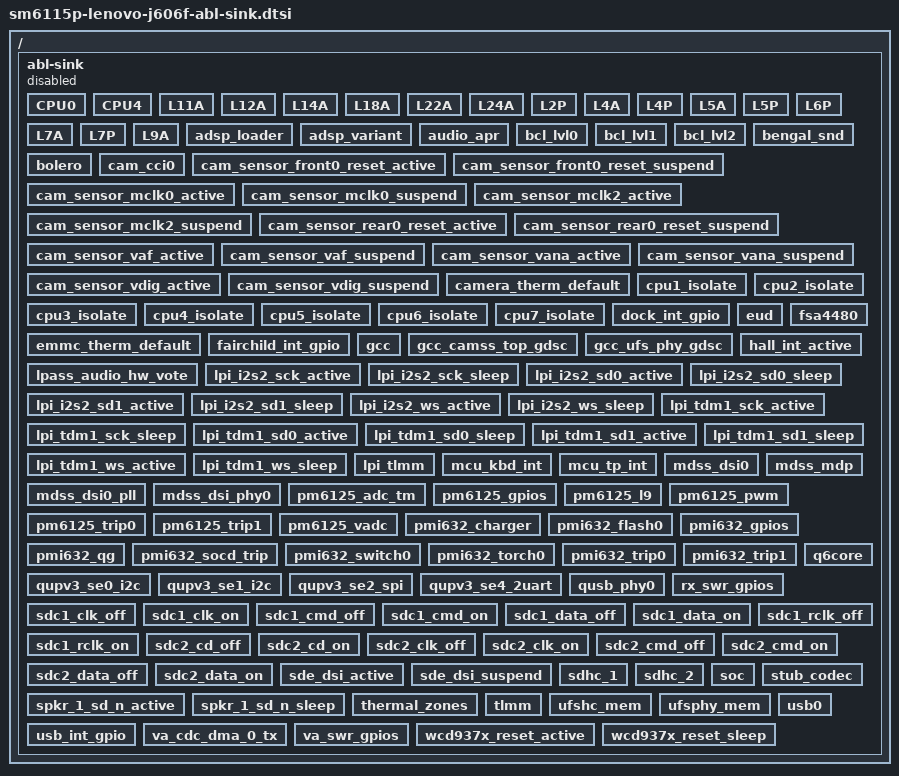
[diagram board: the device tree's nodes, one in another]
// SPDX-License-Identifier: (GPL-2.0+ OR BSD-3-Clause)
/*
 * Lenovo ABL always applies the stock dtbo overlay ("Lenovo P11 WIFI PVT") to the
 * DTB from boot.img and refuses to boot if the overlay's __fixups__ cannot be resolved.
 * Give every label the stock overlay references a dummy node inside a disabled,
 * compatible-less container, so the overlay lands there and nothing probes it.
 * Generated by scripts/gen_abl_sink_dtsi.py from the stock dtbo, do not edit.
 */

/ {
	abl-sink {
		status = "disabled";

		CPU0 {
			phandle = <0xa0001>;
		};
		CPU4 {
			phandle = <0xa0002>;
		};
		L11A {
			phandle = <0xa0003>;
		};
		L12A {
			phandle = <0xa0004>;
		};
		L14A {
			phandle = <0xa0005>;
		};
		L18A {
			phandle = <0xa0006>;
		};
		L22A {
			phandle = <0xa0007>;
		};
		L24A {
			phandle = <0xa0008>;
		};
		L2P {
			phandle = <0xa0009>;
		};
		L4A {
			phandle = <0xa000a>;
		};
		L4P {
			phandle = <0xa000b>;
		};
		L5A {
			phandle = <0xa000c>;
		};
		L5P {
			phandle = <0xa000d>;
		};
		L6P {
			phandle = <0xa000e>;
		};
		L7A {
			phandle = <0xa000f>;
		};
		L7P {
			phandle = <0xa0010>;
		};
		L9A {
			phandle = <0xa0011>;
		};
		adsp_loader {
			phandle = <0xa0012>;
		};
		adsp_variant {
			phandle = <0xa0013>;
		};
		audio_apr {
			phandle = <0xa0014>;
		};
		bcl_lvl0 {
			phandle = <0xa0015>;
		};
		bcl_lvl1 {
			phandle = <0xa0016>;
		};
		bcl_lvl2 {
			phandle = <0xa0017>;
		};
		bengal_snd {
			phandle = <0xa0018>;
		};
		bolero {
			phandle = <0xa0019>;
		};
		cam_cci0 {
			phandle = <0xa001a>;
		};
		cam_sensor_front0_reset_active {
			phandle = <0xa001b>;
		};
		cam_sensor_front0_reset_suspend {
			phandle = <0xa001c>;
		};
		cam_sensor_mclk0_active {
			phandle = <0xa001d>;
		};
		cam_sensor_mclk0_suspend {
			phandle = <0xa001e>;
		};
		cam_sensor_mclk2_active {
			phandle = <0xa001f>;
		};
		cam_sensor_mclk2_suspend {
			phandle = <0xa0020>;
		};
		cam_sensor_rear0_reset_active {
			phandle = <0xa0021>;
		};
		cam_sensor_rear0_reset_suspend {
			phandle = <0xa0022>;
		};
		cam_sensor_vaf_active {
			phandle = <0xa0023>;
		};
		cam_sensor_vaf_suspend {
			phandle = <0xa0024>;
		};
		cam_sensor_vana_active {
			phandle = <0xa0025>;
		};
		cam_sensor_vana_suspend {
			phandle = <0xa0026>;
		};
		cam_sensor_vdig_active {
			phandle = <0xa0027>;
		};
		cam_sensor_vdig_suspend {
			phandle = <0xa0028>;
		};
		camera_therm_default {
			phandle = <0xa0029>;
		};
		cpu1_isolate {
			phandle = <0xa002a>;
		};
		cpu2_isolate {
			phandle = <0xa002b>;
		};
		cpu3_isolate {
			phandle = <0xa002c>;
		};
		cpu4_isolate {
			phandle = <0xa002d>;
		};
		cpu5_isolate {
			phandle = <0xa002e>;
		};
		cpu6_isolate {
			phandle = <0xa002f>;
		};
		cpu7_isolate {
			phandle = <0xa0030>;
		};
		dock_int_gpio {
			phandle = <0xa0031>;
		};
		emmc_therm_default {
			phandle = <0xa0032>;
		};
		eud {
			phandle = <0xa0033>;
		};
		fairchild_int_gpio {
			phandle = <0xa0034>;
		};
		fsa4480 {
			phandle = <0xa0035>;
		};
		gcc {
			phandle = <0xa0036>;
		};
		gcc_camss_top_gdsc {
			phandle = <0xa0037>;
		};
		gcc_ufs_phy_gdsc {
			phandle = <0xa0038>;
		};
		hall_int_active {
			phandle = <0xa0039>;
		};
		lpass_audio_hw_vote {
			phandle = <0xa003a>;
		};
		lpi_i2s2_sck_active {
			phandle = <0xa003b>;
		};
		lpi_i2s2_sck_sleep {
			phandle = <0xa003c>;
		};
		lpi_i2s2_sd0_active {
			phandle = <0xa003d>;
		};
		lpi_i2s2_sd0_sleep {
			phandle = <0xa003e>;
		};
		lpi_i2s2_sd1_active {
			phandle = <0xa003f>;
		};
		lpi_i2s2_sd1_sleep {
			phandle = <0xa0040>;
		};
		lpi_i2s2_ws_active {
			phandle = <0xa0041>;
		};
		lpi_i2s2_ws_sleep {
			phandle = <0xa0042>;
		};
		lpi_tdm1_sck_active {
			phandle = <0xa0043>;
		};
		lpi_tdm1_sck_sleep {
			phandle = <0xa0044>;
		};
		lpi_tdm1_sd0_active {
			phandle = <0xa0045>;
		};
		lpi_tdm1_sd0_sleep {
			phandle = <0xa0046>;
		};
		lpi_tdm1_sd1_active {
			phandle = <0xa0047>;
		};
		lpi_tdm1_sd1_sleep {
			phandle = <0xa0048>;
		};
		lpi_tdm1_ws_active {
			phandle = <0xa0049>;
		};
		lpi_tdm1_ws_sleep {
			phandle = <0xa004a>;
		};
		lpi_tlmm {
			phandle = <0xa004b>;
		};
		mcu_kbd_int {
			phandle = <0xa004c>;
		};
		mcu_tp_int {
			phandle = <0xa004d>;
		};
		mdss_dsi0 {
			phandle = <0xa004e>;
		};
		mdss_dsi0_pll {
			phandle = <0xa004f>;
		};
		mdss_dsi_phy0 {
			phandle = <0xa0050>;
		};
		mdss_mdp {
			phandle = <0xa0051>;
		};
		pm6125_adc_tm {
			phandle = <0xa0052>;
		};
		pm6125_gpios {
			phandle = <0xa0053>;
		};
		pm6125_l9 {
			phandle = <0xa0054>;
		};
		pm6125_pwm {
			phandle = <0xa0055>;
		};
		pm6125_trip0 {
			phandle = <0xa0056>;
		};
		pm6125_trip1 {
			phandle = <0xa0057>;
		};
		pm6125_vadc {
			phandle = <0xa0058>;
		};
		pmi632_charger {
			phandle = <0xa0059>;
		};
		pmi632_flash0 {
			phandle = <0xa005a>;
		};
		pmi632_gpios {
			phandle = <0xa005b>;
		};
		pmi632_qg {
			phandle = <0xa005c>;
		};
		pmi632_socd_trip {
			phandle = <0xa005d>;
		};
		pmi632_switch0 {
			phandle = <0xa005e>;
		};
		pmi632_torch0 {
			phandle = <0xa005f>;
		};
		pmi632_trip0 {
			phandle = <0xa0060>;
		};
		pmi632_trip1 {
			phandle = <0xa0061>;
		};
		q6core {
			phandle = <0xa0062>;
		};
		qupv3_se0_i2c {
			phandle = <0xa0063>;
		};
		qupv3_se1_i2c {
			phandle = <0xa0064>;
		};
		qupv3_se2_spi {
			phandle = <0xa0065>;
		};
		qupv3_se4_2uart {
			phandle = <0xa0066>;
		};
		qusb_phy0 {
			phandle = <0xa0067>;
		};
		rx_swr_gpios {
			phandle = <0xa0068>;
		};
		sdc1_clk_off {
			phandle = <0xa0069>;
		};
		sdc1_clk_on {
			phandle = <0xa006a>;
		};
		sdc1_cmd_off {
			phandle = <0xa006b>;
		};
		sdc1_cmd_on {
			phandle = <0xa006c>;
		};
		sdc1_data_off {
			phandle = <0xa006d>;
		};
		sdc1_data_on {
			phandle = <0xa006e>;
		};
		sdc1_rclk_off {
			phandle = <0xa006f>;
		};
		sdc1_rclk_on {
			phandle = <0xa0070>;
		};
		sdc2_cd_off {
			phandle = <0xa0071>;
		};
		sdc2_cd_on {
			phandle = <0xa0072>;
		};
		sdc2_clk_off {
			phandle = <0xa0073>;
		};
		sdc2_clk_on {
			phandle = <0xa0074>;
		};
		sdc2_cmd_off {
			phandle = <0xa0075>;
		};
		sdc2_cmd_on {
			phandle = <0xa0076>;
		};
		sdc2_data_off {
			phandle = <0xa0077>;
		};
		sdc2_data_on {
			phandle = <0xa0078>;
		};
		sde_dsi_active {
			phandle = <0xa0079>;
		};
		sde_dsi_suspend {
			phandle = <0xa007a>;
		};
		sdhc_1 {
			phandle = <0xa007b>;
		};
		sdhc_2 {
			phandle = <0xa007c>;
		};
		soc {
			phandle = <0xa007d>;
		};
		spkr_1_sd_n_active {
			phandle = <0xa007e>;
		};
		spkr_1_sd_n_sleep {
			phandle = <0xa007f>;
		};
		stub_codec {
			phandle = <0xa0080>;
		};
		thermal_zones {
			phandle = <0xa0081>;
		};
		tlmm {
			phandle = <0xa0082>;
		};
		ufshc_mem {
			phandle = <0xa0083>;
		};
		ufsphy_mem {
			phandle = <0xa0084>;
		};
		usb0 {
			phandle = <0xa0085>;
		};
		usb_int_gpio {
			phandle = <0xa0086>;
		};
		va_cdc_dma_0_tx {
			phandle = <0xa0087>;
		};
		va_swr_gpios {
			phandle = <0xa0088>;
		};
		wcd937x_reset_active {
			phandle = <0xa0089>;
		};
		wcd937x_reset_sleep {
			phandle = <0xa008a>;
		};
	};

	__symbols__ {
		CPU0 = "/abl-sink/CPU0";
		CPU4 = "/abl-sink/CPU4";
		L11A = "/abl-sink/L11A";
		L12A = "/abl-sink/L12A";
		L14A = "/abl-sink/L14A";
		L18A = "/abl-sink/L18A";
		L22A = "/abl-sink/L22A";
		L24A = "/abl-sink/L24A";
		L2P = "/abl-sink/L2P";
		L4A = "/abl-sink/L4A";
		L4P = "/abl-sink/L4P";
		L5A = "/abl-sink/L5A";
		L5P = "/abl-sink/L5P";
		L6P = "/abl-sink/L6P";
		L7A = "/abl-sink/L7A";
		L7P = "/abl-sink/L7P";
		L9A = "/abl-sink/L9A";
		adsp_loader = "/abl-sink/adsp_loader";
		adsp_variant = "/abl-sink/adsp_variant";
		audio_apr = "/abl-sink/audio_apr";
		bcl_lvl0 = "/abl-sink/bcl_lvl0";
		bcl_lvl1 = "/abl-sink/bcl_lvl1";
		bcl_lvl2 = "/abl-sink/bcl_lvl2";
		bengal_snd = "/abl-sink/bengal_snd";
		bolero = "/abl-sink/bolero";
		cam_cci0 = "/abl-sink/cam_cci0";
		cam_sensor_front0_reset_active = "/abl-sink/cam_sensor_front0_reset_active";
		cam_sensor_front0_reset_suspend = "/abl-sink/cam_sensor_front0_reset_suspend";
		cam_sensor_mclk0_active = "/abl-sink/cam_sensor_mclk0_active";
		cam_sensor_mclk0_suspend = "/abl-sink/cam_sensor_mclk0_suspend";
		cam_sensor_mclk2_active = "/abl-sink/cam_sensor_mclk2_active";
		cam_sensor_mclk2_suspend = "/abl-sink/cam_sensor_mclk2_suspend";
		cam_sensor_rear0_reset_active = "/abl-sink/cam_sensor_rear0_reset_active";
		cam_sensor_rear0_reset_suspend = "/abl-sink/cam_sensor_rear0_reset_suspend";
		cam_sensor_vaf_active = "/abl-sink/cam_sensor_vaf_active";
		cam_sensor_vaf_suspend = "/abl-sink/cam_sensor_vaf_suspend";
		cam_sensor_vana_active = "/abl-sink/cam_sensor_vana_active";
		cam_sensor_vana_suspend = "/abl-sink/cam_sensor_vana_suspend";
		cam_sensor_vdig_active = "/abl-sink/cam_sensor_vdig_active";
		cam_sensor_vdig_suspend = "/abl-sink/cam_sensor_vdig_suspend";
		camera_therm_default = "/abl-sink/camera_therm_default";
		cpu1_isolate = "/abl-sink/cpu1_isolate";
		cpu2_isolate = "/abl-sink/cpu2_isolate";
		cpu3_isolate = "/abl-sink/cpu3_isolate";
		cpu4_isolate = "/abl-sink/cpu4_isolate";
		cpu5_isolate = "/abl-sink/cpu5_isolate";
		cpu6_isolate = "/abl-sink/cpu6_isolate";
		cpu7_isolate = "/abl-sink/cpu7_isolate";
		dock_int_gpio = "/abl-sink/dock_int_gpio";
		emmc_therm_default = "/abl-sink/emmc_therm_default";
		eud = "/abl-sink/eud";
		fairchild_int_gpio = "/abl-sink/fairchild_int_gpio";
		fsa4480 = "/abl-sink/fsa4480";
		gcc = "/abl-sink/gcc";
		gcc_camss_top_gdsc = "/abl-sink/gcc_camss_top_gdsc";
		gcc_ufs_phy_gdsc = "/abl-sink/gcc_ufs_phy_gdsc";
		hall_int_active = "/abl-sink/hall_int_active";
		lpass_audio_hw_vote = "/abl-sink/lpass_audio_hw_vote";
		lpi_i2s2_sck_active = "/abl-sink/lpi_i2s2_sck_active";
		lpi_i2s2_sck_sleep = "/abl-sink/lpi_i2s2_sck_sleep";
		lpi_i2s2_sd0_active = "/abl-sink/lpi_i2s2_sd0_active";
		lpi_i2s2_sd0_sleep = "/abl-sink/lpi_i2s2_sd0_sleep";
		lpi_i2s2_sd1_active = "/abl-sink/lpi_i2s2_sd1_active";
		lpi_i2s2_sd1_sleep = "/abl-sink/lpi_i2s2_sd1_sleep";
		lpi_i2s2_ws_active = "/abl-sink/lpi_i2s2_ws_active";
		lpi_i2s2_ws_sleep = "/abl-sink/lpi_i2s2_ws_sleep";
		lpi_tdm1_sck_active = "/abl-sink/lpi_tdm1_sck_active";
		lpi_tdm1_sck_sleep = "/abl-sink/lpi_tdm1_sck_sleep";
		lpi_tdm1_sd0_active = "/abl-sink/lpi_tdm1_sd0_active";
		lpi_tdm1_sd0_sleep = "/abl-sink/lpi_tdm1_sd0_sleep";
		lpi_tdm1_sd1_active = "/abl-sink/lpi_tdm1_sd1_active";
		lpi_tdm1_sd1_sleep = "/abl-sink/lpi_tdm1_sd1_sleep";
		lpi_tdm1_ws_active = "/abl-sink/lpi_tdm1_ws_active";
		lpi_tdm1_ws_sleep = "/abl-sink/lpi_tdm1_ws_sleep";
		lpi_tlmm = "/abl-sink/lpi_tlmm";
		mcu_kbd_int = "/abl-sink/mcu_kbd_int";
		mcu_tp_int = "/abl-sink/mcu_tp_int";
		mdss_dsi0 = "/abl-sink/mdss_dsi0";
		mdss_dsi0_pll = "/abl-sink/mdss_dsi0_pll";
		mdss_dsi_phy0 = "/abl-sink/mdss_dsi_phy0";
		mdss_mdp = "/abl-sink/mdss_mdp";
		pm6125_adc_tm = "/abl-sink/pm6125_adc_tm";
		pm6125_gpios = "/abl-sink/pm6125_gpios";
		pm6125_l9 = "/abl-sink/pm6125_l9";
		pm6125_pwm = "/abl-sink/pm6125_pwm";
		pm6125_trip0 = "/abl-sink/pm6125_trip0";
		pm6125_trip1 = "/abl-sink/pm6125_trip1";
		pm6125_vadc = "/abl-sink/pm6125_vadc";
		pmi632_charger = "/abl-sink/pmi632_charger";
		pmi632_flash0 = "/abl-sink/pmi632_flash0";
		pmi632_gpios = "/abl-sink/pmi632_gpios";
		pmi632_qg = "/abl-sink/pmi632_qg";
		pmi632_socd_trip = "/abl-sink/pmi632_socd_trip";
		pmi632_switch0 = "/abl-sink/pmi632_switch0";
		pmi632_torch0 = "/abl-sink/pmi632_torch0";
		pmi632_trip0 = "/abl-sink/pmi632_trip0";
		pmi632_trip1 = "/abl-sink/pmi632_trip1";
		q6core = "/abl-sink/q6core";
		qupv3_se0_i2c = "/abl-sink/qupv3_se0_i2c";
		qupv3_se1_i2c = "/abl-sink/qupv3_se1_i2c";
		qupv3_se2_spi = "/abl-sink/qupv3_se2_spi";
		qupv3_se4_2uart = "/abl-sink/qupv3_se4_2uart";
		qusb_phy0 = "/abl-sink/qusb_phy0";
		rx_swr_gpios = "/abl-sink/rx_swr_gpios";
		sdc1_clk_off = "/abl-sink/sdc1_clk_off";
		sdc1_clk_on = "/abl-sink/sdc1_clk_on";
		sdc1_cmd_off = "/abl-sink/sdc1_cmd_off";
		sdc1_cmd_on = "/abl-sink/sdc1_cmd_on";
		sdc1_data_off = "/abl-sink/sdc1_data_off";
		sdc1_data_on = "/abl-sink/sdc1_data_on";
		sdc1_rclk_off = "/abl-sink/sdc1_rclk_off";
		sdc1_rclk_on = "/abl-sink/sdc1_rclk_on";
		sdc2_cd_off = "/abl-sink/sdc2_cd_off";
		sdc2_cd_on = "/abl-sink/sdc2_cd_on";
		sdc2_clk_off = "/abl-sink/sdc2_clk_off";
		sdc2_clk_on = "/abl-sink/sdc2_clk_on";
		sdc2_cmd_off = "/abl-sink/sdc2_cmd_off";
		sdc2_cmd_on = "/abl-sink/sdc2_cmd_on";
		sdc2_data_off = "/abl-sink/sdc2_data_off";
		sdc2_data_on = "/abl-sink/sdc2_data_on";
		sde_dsi_active = "/abl-sink/sde_dsi_active";
		sde_dsi_suspend = "/abl-sink/sde_dsi_suspend";
		sdhc_1 = "/abl-sink/sdhc_1";
		sdhc_2 = "/abl-sink/sdhc_2";
		soc = "/abl-sink/soc";
		spkr_1_sd_n_active = "/abl-sink/spkr_1_sd_n_active";
		spkr_1_sd_n_sleep = "/abl-sink/spkr_1_sd_n_sleep";
		stub_codec = "/abl-sink/stub_codec";
		thermal_zones = "/abl-sink/thermal_zones";
		tlmm = "/abl-sink/tlmm";
		ufshc_mem = "/abl-sink/ufshc_mem";
		ufsphy_mem = "/abl-sink/ufsphy_mem";
		usb0 = "/abl-sink/usb0";
		usb_int_gpio = "/abl-sink/usb_int_gpio";
		va_cdc_dma_0_tx = "/abl-sink/va_cdc_dma_0_tx";
		va_swr_gpios = "/abl-sink/va_swr_gpios";
		wcd937x_reset_active = "/abl-sink/wcd937x_reset_active";
		wcd937x_reset_sleep = "/abl-sink/wcd937x_reset_sleep";
	};
};

